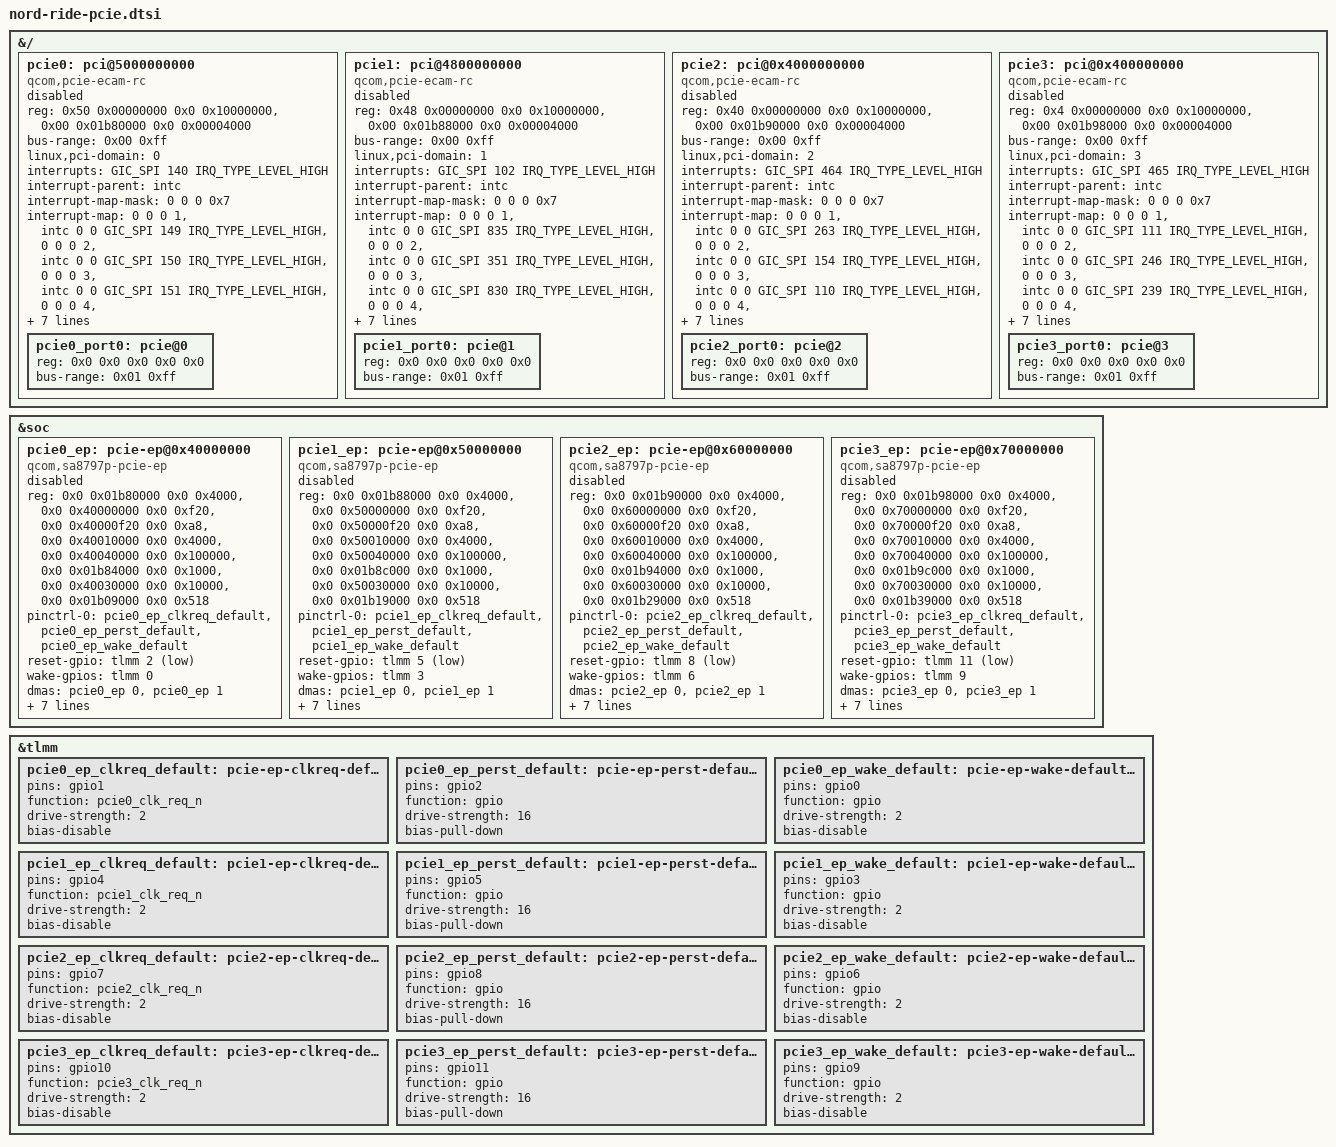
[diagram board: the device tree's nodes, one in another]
// SPDX-License-Identifier: BSD-3-Clause
/*
 * Copyright (c) Qualcomm Technologies, Inc. and/or its subsidiaries.
 *
 * nord-ride PCIe complex. Ported from QLI 1.0 sa8797p-pcie.dtsi, which QLI 1.0
 * pulled into the COMMON platform base (sa8x97p.dtsi) so every board carried
 * the PCIe controllers with pcie0_ep left status="disabled"; the pcie-ep
 * variant board then only flipped &pcie0_ep to "okay". We mirror that layering:
 * this file is included by the common nord-ride_overlay so all nord variants
 * carry the (disabled) PCIe complex, and nord-ride-pcie-ep.dtso enables the EP.
 *
 * OVERLAY ADAPTATION: QLI 1.0 authored pcie0..3 under a bare "/ {}" root, valid
 * because it was #included into a full .dts (single compile, real root). Here
 * the content lives in a /plugin/ overlay, where a bare "/ {}" sets the overlay's
 * own root and is discarded by fdtoverlay. The host-bridge block is therefore
 * wrapped in &{/} (target-path "/") so it merges into the base root. The pcie0_ep
 * node stays under &soc as in QLI 1.0. Content is otherwise verbatim.
 *
 * Deps (all resolve against the upstream base + our additions):
 *   &pcie_smmu  - nord-addons.dtsi (iommu@9980000)
 *   &gic_its    - base msi-controller@17040000
 *   &intc, &tlmm, &soc - base
 *   pcie0_ep_*_default pinctrl states - defined below under &tlmm
 */

#include <dt-bindings/gpio/gpio.h>

&{/} {
	pcie0: pci@5000000000 {
		compatible = "qcom,pcie-ecam-rc";
		reg = <0x50 0x00000000 0x0 0x10000000>,
		      <0x00 0x01b80000 0x0 0x00004000>;
		reg-names = "dbi", "parf";

		device_type = "pci";

		#address-cells = <3>;
		#size-cells = <2>;

		ranges = <0x01000000 0x0 0x40000000 0x0 0x40000000 0x0 0x100000>,
			<0x02000000 0x0 0x40100000 0x0 0x40100000 0x0 0x7000000>,
			<0x43000000 0x50 0x10100000 0x50 0x10100000 0x8 0x00000000>;
		bus-range = <0x00 0xff>;

		linux,pci-domain = <0>;

		interrupts = <GIC_SPI 140 IRQ_TYPE_LEVEL_HIGH>;
		interrupt-names = "global_int";

		interrupt-parent = <&intc>;
		#interrupt-cells = <1>;
		interrupt-map-mask = <0 0 0 0x7>;
		interrupt-map = <0 0 0 1 &intc 0 0 GIC_SPI 149 IRQ_TYPE_LEVEL_HIGH>, //INTa
					<0 0 0 2 &intc 0 0 GIC_SPI 150 IRQ_TYPE_LEVEL_HIGH>, //INTb
					<0 0 0 3 &intc 0 0 GIC_SPI 151 IRQ_TYPE_LEVEL_HIGH>, //INTc
					<0 0 0 4 &intc 0 0 GIC_SPI 152 IRQ_TYPE_LEVEL_HIGH>; //INTd

		dma-coherent;
		iommu-map = <0x0 &pcie_smmu 0x0000 0x1>,
				<0x100 &pcie_smmu 0x0100 0x1>,
				<0x200 &pcie_smmu 0x0200 0x1>,
				<0x300 &pcie_smmu 0x0300 0x1>;

		msi-map = <0x0 &gic_its 0x80000 0x10000>;

		status = "disabled";

		pcie0_port0: pcie@0 {
				device_type = "pci";
				reg = <0x0 0x0 0x0 0x0 0x0>;
				bus-range = <0x01 0xff>;
				#address-cells = <3>;
				#size-cells = <2>;
				ranges;
		};
	};

	pcie1: pci@4800000000 {
		compatible = "qcom,pcie-ecam-rc";
		reg = <0x48 0x00000000 0x0 0x10000000>,
		      <0x00 0x01b88000 0x0 0x00004000>;
		reg-names = "dbi", "parf";

		device_type = "pci";

		#address-cells = <3>;
		#size-cells = <2>;

		ranges = <0x01000000 0x0 0x48000000 0x0 0x48000000 0x0 0x100000>,
			<0x02000000 0x0 0x48100000 0x0 0x48100000 0x0 0x7000000>,
			<0x43000000 0x48 0x10100000 0x48 0x10100000 0x4 0x00000000>;
		bus-range = <0x00 0xff>;

		linux,pci-domain = <1>;

		interrupts = <GIC_SPI 102 IRQ_TYPE_LEVEL_HIGH>;
		interrupt-names = "global_int";

		interrupt-parent = <&intc>;
		#interrupt-cells = <1>;
		interrupt-map-mask = <0 0 0 0x7>;
		interrupt-map = <0 0 0 1 &intc 0 0 GIC_SPI 835 IRQ_TYPE_LEVEL_HIGH>, //INTa
					<0 0 0 2 &intc 0 0 GIC_SPI 351 IRQ_TYPE_LEVEL_HIGH>, //INTb
					<0 0 0 3 &intc 0 0 GIC_SPI 830 IRQ_TYPE_LEVEL_HIGH>, //INTc
					<0 0 0 4 &intc 0 0 GIC_SPI 348 IRQ_TYPE_LEVEL_HIGH>; //INTd

		msi-map = <0x0 &gic_its 0x90000 0x10000>;

		dma-coherent;
		iommu-map = <0x0 &pcie_smmu 0x10000 0x1>,
				<0x100 &pcie_smmu 0x10100 0x1>,
				<0x200 &pcie_smmu 0x10200 0x1>,
				<0x300 &pcie_smmu 0x10300 0x1>;

		status = "disabled";

		pcie1_port0: pcie@1 {
				device_type = "pci";
				reg = <0x0 0x0 0x0 0x0 0x0>;
				bus-range = <0x01 0xff>;
				#address-cells = <3>;
				#size-cells = <2>;
				ranges;
		};
	};

	pcie2: pci@0x4000000000 {
		compatible = "qcom,pcie-ecam-rc";
		reg = <0x40 0x00000000 0x0 0x10000000>,
		      <0x00 0x01b90000 0x0 0x00004000>;
		reg-names = "dbi", "parf";

		device_type = "pci";

		#address-cells = <3>;
		#size-cells = <2>;

		ranges = <0x01000000 0x0 0x50000000 0x0 0x50000000 0x0 0x100000>,
			<0x02000000 0x0 0x50100000 0x0 0x50100000 0x0 0x7000000>,
			<0x43000000 0x40 0x10100000 0x40 0x10100000 0x4 0x00000000>;
		bus-range = <0x00 0xff>;

		linux,pci-domain = <2>;

		interrupts = <GIC_SPI 464 IRQ_TYPE_LEVEL_HIGH>;
		interrupt-names = "global_int";

		interrupt-parent = <&intc>;
		#interrupt-cells = <1>;
		interrupt-map-mask = <0 0 0 0x7>;
		interrupt-map = <0 0 0 1 &intc 0 0 GIC_SPI 263 IRQ_TYPE_LEVEL_HIGH>, //INTa
					<0 0 0 2 &intc 0 0 GIC_SPI 154 IRQ_TYPE_LEVEL_HIGH>, //INTb
					<0 0 0 3 &intc 0 0 GIC_SPI 110 IRQ_TYPE_LEVEL_HIGH>, //INTc
					<0 0 0 4 &intc 0 0 GIC_SPI 258 IRQ_TYPE_LEVEL_HIGH>; //INTd

		msi-map = <0x0 &gic_its 0xa0000 0x10000>;

		dma-coherent;
		iommu-map = <0x0 &pcie_smmu 0x20000 0x1>,
				<0x100 &pcie_smmu 0x20100 0x1>,
				<0x200 &pcie_smmu 0x20200 0x1>,
				<0x300 &pcie_smmu 0x20300 0x1>;

		status = "disabled";

		pcie2_port0: pcie@2 {
				device_type = "pci";
				reg = <0x0 0x0 0x0 0x0 0x0>;
				bus-range = <0x01 0xff>;
				#address-cells = <3>;
				#size-cells = <2>;
				ranges;
		};
	};

	pcie3: pci@0x400000000 {
		compatible = "qcom,pcie-ecam-rc";
		reg = <0x4 0x00000000 0x0 0x10000000>,
		      <0x00 0x01b98000 0x0 0x00004000>;
		reg-names = "dbi", "parf";

		device_type = "pci";

		#address-cells = <3>;
		#size-cells = <2>;

		ranges = <0x01000000 0x0 0x58000000 0x0 0x58000000 0x0 0x100000>,
			<0x02000000 0x0 0x58100000 0x0 0x58100000 0x0 0x7000000>,
			<0x43000000 0x4 0x10100000 0x4 0x10100000 0x0 0x80000000>;
		bus-range = <0x00 0xff>;

		linux,pci-domain = <3>;

		interrupts = <GIC_SPI 465 IRQ_TYPE_LEVEL_HIGH>;
		interrupt-names = "global_int";

		interrupt-parent = <&intc>;
		#interrupt-cells = <1>;
		interrupt-map-mask = <0 0 0 0x7>;
		interrupt-map = <0 0 0 1 &intc 0 0 GIC_SPI 111 IRQ_TYPE_LEVEL_HIGH>, //INTa
					<0 0 0 2 &intc 0 0 GIC_SPI 246 IRQ_TYPE_LEVEL_HIGH>, //INTb
					<0 0 0 3 &intc 0 0 GIC_SPI 239 IRQ_TYPE_LEVEL_HIGH>, //INTc
					<0 0 0 4 &intc 0 0 GIC_SPI 234 IRQ_TYPE_LEVEL_HIGH>; //INTd

		msi-map = <0x0 &gic_its 0xb0000 0x10000>;

		dma-coherent;
		iommu-map = <0x0 &pcie_smmu 0x30000 0x1>,
				<0x100 &pcie_smmu 0x30100 0x1>,
				<0x200 &pcie_smmu 0x30200 0x1>,
				<0x300 &pcie_smmu 0x30300 0x1>;

		status = "disabled";

		pcie3_port0: pcie@3 {
				device_type = "pci";
				reg = <0x0 0x0 0x0 0x0 0x0>;
				bus-range = <0x01 0xff>;
				#address-cells = <3>;
				#size-cells = <2>;
				ranges;
		};
	};
};

&soc {
	pcie0_ep: pcie-ep@0x40000000 {
		compatible = "qcom,sa8797p-pcie-ep";
		reg = <0x0 0x01b80000 0x0 0x4000>,
		      <0x0 0x40000000 0x0 0xf20>,
		      <0x0 0x40000f20 0x0 0xa8>,
		      <0x0 0x40010000 0x0 0x4000>,
		      <0x0 0x40040000 0x0 0x100000>,
		      <0x0 0x01b84000 0x0 0x1000>,
		      <0x0 0x40030000 0x0 0x10000>,
		      <0x0 0x01b09000 0x0 0x518>;
		reg-names = "parf", "dbi", "elbi", "atu", "addr_space",
			    "mmio", "dma", "phy_pcs";

		pinctrl-names = "default";
		pinctrl-0 = <&pcie0_ep_clkreq_default &pcie0_ep_perst_default
				&pcie0_ep_wake_default>;

		reset-gpio = <&tlmm 2 GPIO_ACTIVE_LOW>;
		wake-gpios = <&tlmm 0 GPIO_ACTIVE_HIGH>;

		#dma-cells = <1>;
		dmas = <&pcie0_ep 0>, <&pcie0_ep 1>;
		dma-names = "rx", "tx";

		interrupts = <GIC_SPI 140 IRQ_TYPE_LEVEL_HIGH>,
			     <GIC_SPI 153 IRQ_TYPE_LEVEL_HIGH>,
			     <GIC_SPI 443 IRQ_TYPE_LEVEL_HIGH>;
		interrupt-names = "global", "doorbell", "dma";

		dma-coherent;
		iommus = <&pcie_smmu 0x0>,
			  <&pcie_smmu 0x100>;

		max-link-speed = <4>;
		num-lanes = <8>;

		status = "disabled";
	};

	pcie1_ep: pcie-ep@0x50000000 {
		compatible = "qcom,sa8797p-pcie-ep";
		reg = <0x0 0x01b88000 0x0 0x4000>,
		      <0x0 0x50000000 0x0 0xf20>,
		      <0x0 0x50000f20 0x0 0xa8>,
		      <0x0 0x50010000 0x0 0x4000>,
		      <0x0 0x50040000 0x0 0x100000>,
		      <0x0 0x01b8c000 0x0 0x1000>,
		      <0x0 0x50030000 0x0 0x10000>,
		      <0x0 0x01b19000 0x0 0x518>;
		reg-names = "parf", "dbi", "elbi", "atu", "addr_space",
			    "mmio", "dma", "phy_pcs";

		pinctrl-names = "default";
		pinctrl-0 = <&pcie1_ep_clkreq_default &pcie1_ep_perst_default
				&pcie1_ep_wake_default>;

		reset-gpio = <&tlmm 5 GPIO_ACTIVE_LOW>;
		wake-gpios = <&tlmm 3 GPIO_ACTIVE_HIGH>;

		#dma-cells = <1>;
		dmas = <&pcie1_ep 0>, <&pcie1_ep 1>;
		dma-names = "rx", "tx";

		interrupts = <GIC_SPI 102 IRQ_TYPE_LEVEL_HIGH>,
			     <GIC_SPI 658 IRQ_TYPE_LEVEL_HIGH>,
			     <GIC_SPI 114 IRQ_TYPE_LEVEL_HIGH>;
		interrupt-names = "global", "doorbell", "dma";

		dma-coherent;
		iommus = <&pcie_smmu 0x10000>,
			  <&pcie_smmu 0x10100>;

		max-link-speed = <4>;
		num-lanes = <4>;

		status = "disabled";
	};

	pcie2_ep: pcie-ep@0x60000000 {
		compatible = "qcom,sa8797p-pcie-ep";
		reg = <0x0 0x01b90000 0x0 0x4000>,
		      <0x0 0x60000000 0x0 0xf20>,
		      <0x0 0x60000f20 0x0 0xa8>,
		      <0x0 0x60010000 0x0 0x4000>,
		      <0x0 0x60040000 0x0 0x100000>,
		      <0x0 0x01b94000 0x0 0x1000>,
		      <0x0 0x60030000 0x0 0x10000>,
		      <0x0 0x01b29000 0x0 0x518>;
		reg-names = "parf", "dbi", "elbi", "atu", "addr_space",
			    "mmio", "dma", "phy_pcs";

		pinctrl-names = "default";
		pinctrl-0 = <&pcie2_ep_clkreq_default &pcie2_ep_perst_default
				&pcie2_ep_wake_default>;

		reset-gpio = <&tlmm 8 GPIO_ACTIVE_LOW>;
		wake-gpios = <&tlmm 6 GPIO_ACTIVE_HIGH>;

		#dma-cells = <1>;
		dmas = <&pcie2_ep 0>, <&pcie2_ep 1>;
		dma-names = "rx", "tx";

		interrupts = <GIC_SPI 464 IRQ_TYPE_LEVEL_HIGH>,
			     <GIC_SPI 108 IRQ_TYPE_LEVEL_HIGH>,
			     <GIC_SPI 235 IRQ_TYPE_LEVEL_HIGH>;
		interrupt-names = "global", "doorbell", "dma";

		dma-coherent;
		iommus = <&pcie_smmu 0x20000>,
			  <&pcie_smmu 0x20100>;

		max-link-speed = <4>;
		num-lanes = <2>;

		status = "disabled";
	};

	pcie3_ep: pcie-ep@0x70000000 {
		compatible = "qcom,sa8797p-pcie-ep";
		reg = <0x0 0x01b98000 0x0 0x4000>,
		      <0x0 0x70000000 0x0 0xf20>,
		      <0x0 0x70000f20 0x0 0xa8>,
		      <0x0 0x70010000 0x0 0x4000>,
		      <0x0 0x70040000 0x0 0x100000>,
		      <0x0 0x01b9c000 0x0 0x1000>,
		      <0x0 0x70030000 0x0 0x10000>,
		      <0x0 0x01b39000 0x0 0x518>;
		reg-names = "parf", "dbi", "elbi", "atu", "addr_space",
			    "mmio", "dma", "phy_pcs";

		pinctrl-names = "default";
		pinctrl-0 = <&pcie3_ep_clkreq_default &pcie3_ep_perst_default
				&pcie3_ep_wake_default>;

		reset-gpio = <&tlmm 11 GPIO_ACTIVE_LOW>;
		wake-gpios = <&tlmm 9 GPIO_ACTIVE_HIGH>;

		#dma-cells = <1>;
		dmas = <&pcie3_ep 0>, <&pcie3_ep 1>;
		dma-names = "rx", "tx";

		interrupts = <GIC_SPI 465 IRQ_TYPE_LEVEL_HIGH>,
			     <GIC_SPI 109 IRQ_TYPE_LEVEL_HIGH>,
			     <GIC_SPI 156 IRQ_TYPE_LEVEL_HIGH>;
		interrupt-names = "global", "doorbell", "dma";

		dma-coherent;
		iommus = <&pcie_smmu 0x30000>,
			  <&pcie_smmu 0x30100>;

		max-link-speed = <4>;
		num-lanes = <2>;

		status = "disabled";
	};
};

&tlmm {
	pcie0_ep_clkreq_default: pcie-ep-clkreq-default-state {
		pins = "gpio1";
		function = "pcie0_clk_req_n";
		drive-strength = <2>;
		bias-disable;
	};

	pcie0_ep_perst_default: pcie-ep-perst-default-state {
		pins = "gpio2";
		function = "gpio";
		drive-strength = <16>;
		bias-pull-down;
	};

	pcie0_ep_wake_default: pcie-ep-wake-default-state {
		pins = "gpio0";
		function = "gpio";
		drive-strength = <2>;
		bias-disable;
	};

	pcie1_ep_clkreq_default: pcie1-ep-clkreq-default-state {
		pins = "gpio4";
		function = "pcie1_clk_req_n";
		drive-strength = <2>;
		bias-disable;
	};

	pcie1_ep_perst_default: pcie1-ep-perst-default-state {
		pins = "gpio5";
		function = "gpio";
		drive-strength = <16>;
		bias-pull-down;
	};

	pcie1_ep_wake_default: pcie1-ep-wake-default-state {
		pins = "gpio3";
		function = "gpio";
		drive-strength = <2>;
		bias-disable;
	};

	pcie2_ep_clkreq_default: pcie2-ep-clkreq-default-state {
		pins = "gpio7";
		function = "pcie2_clk_req_n";
		drive-strength = <2>;
		bias-disable;
	};

	pcie2_ep_perst_default: pcie2-ep-perst-default-state {
		pins = "gpio8";
		function = "gpio";
		drive-strength = <16>;
		bias-pull-down;
	};

	pcie2_ep_wake_default: pcie2-ep-wake-default-state {
		pins = "gpio6";
		function = "gpio";
		drive-strength = <2>;
		bias-disable;
	};

	pcie3_ep_clkreq_default: pcie3-ep-clkreq-default-state {
		pins = "gpio10";
		function = "pcie3_clk_req_n";
		drive-strength = <2>;
		bias-disable;
	};

	pcie3_ep_perst_default: pcie3-ep-perst-default-state {
		pins = "gpio11";
		function = "gpio";
		drive-strength = <16>;
		bias-pull-down;
	};

	pcie3_ep_wake_default: pcie3-ep-wake-default-state {
		pins = "gpio9";
		function = "gpio";
		drive-strength = <2>;
		bias-disable;
	};
};
